# STM32U385 register map
File version: 1.0
CPU: CM33 r0p1, little endian, MPU, FPU, 4 interrupt priority bits
Registers are 32-bit, read-write, reset 0x0 unless marked. A register's access mark holds for its fields unless they carry their own. Offsets are from the block's base; [hi:lo] are bit positions; {n}, {i} and the like mark numbered series.

## PWR — PWR Address block
Base 0x40030800
Same registers: SEC_PWR 0x50030800
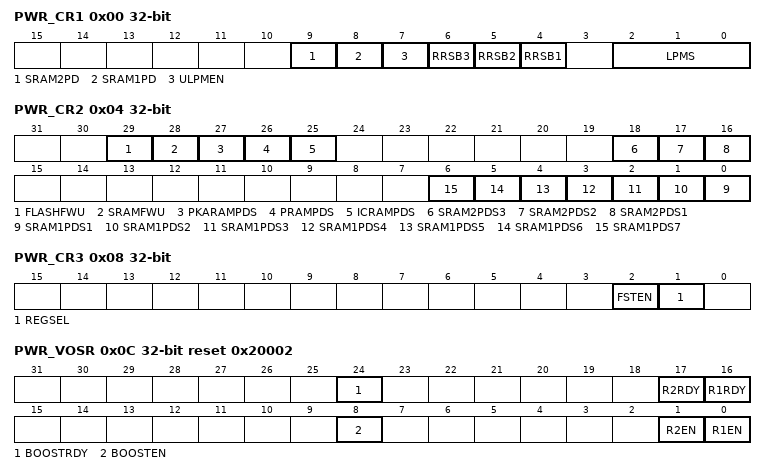
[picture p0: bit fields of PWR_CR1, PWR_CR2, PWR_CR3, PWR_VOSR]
0x00 PWR_CR1 — PWR control register 1
  [9] SRAM2PD — This bit is used to reduce the consumption by powering off the SRAM2. 0: SRAM2 powered on 1: SRAM2 powered off Note: When this bit is cleared to 0, wait for more than 1.6us before accessing the SRAM.
    0=SRAM2 powered on; 1=SRAM2 powered off
  [8] SRAM1PD — This bit is used to reduce the consumption by powering off the SRAM1. 0: SRAM1 powered on 1: SRAM1 powered off Note: When this bit is cleared to 0, wait for more than 1.6us before accessing the SRAM.
    0=SRAM1 powered on; 1=SRAM1 powered off
  [7] ULPMEN — This bit is used to reduce the consumption by configuring the BOR in discontinuous mode. This bit has effect only when the BOR level 0 is selected and when the device is in Standby mode. This bit must be set to reach the lowest power consumption in Standby mode. 0: BOR level 0 operating in continuous (normal) mode in Standby mode 1: BOR level 0 operating in discontinuous (ultra-low power) mode in Standby mode
    0=BOR level 0 operating in continuous (normal) mode in Standby mode; 1=BOR level 0 operating in discontinuous (ultra-low power) mode in Standby mode
  [6] RRSB3 — This bit is used to keep the SRAM2 page 3 content in Standby mode. The SRAM2 page 3 corresponds to the last 32 Kbytes of the SRAM2 (from SRAM2 base address + 0x8000 to SRAM2 base address + 0xFFFF). 0: SRAM2 page3 content not retained in Standby mode 1: SRAM2 page3 content retained in Standby mode Note: This bit has no effect in Shutdown mode.
    0=SRAM2 page3 content not retained in Standby mode; 1=SRAM2 page3 content retained in Standby mode
  [5] RRSB2 — This bit is used to keep the SRAM2 page 2 content in Standby mode. The SRAM2 page 2 corresponds to the 24 Kbytes of the SRAM2 (from SRAM2 base address + 0x2000 to SRAM2 base address + 0x7FFF). 0: SRAM2 page2 content not retained in Standby mode 1: SRAM2 page2 content retained in Standby mode Note: This bit has no effect in Shutdown mode.
    0=SRAM2 page2 content not retained in Standby mode; 1=SRAM2 page2 content retained in Standby mode
  [4] RRSB1 — This bit is used to keep the SRAM2 page 1 content in Standby mode. The SRAM2 page 1 corresponds to the first 8 Kbytes of the SRAM2 (from SRAM2 base address to SRAM2 base address + 0x1FFF). 0: SRAM2 page1 content not retained in Standby mode 1: SRAM2 page1 content retained in Standby mode Note: This bit has no effect in Shutdown mode.
    0=SRAM2 page1 content not retained in Standby mode; 1=SRAM2 page1 content retained in Standby mode
  [2:0] LPMS — These bits select the low-power mode entered when the CPU enters the Deepsleep mode. 000: Stop 0 mode 001: Stop 1 mode 010: Stop 2 mode 011: Stop 3 mode 100-101: Standby mode 110-111: Shutdown mode
    {v}=Stop {v} mode (v=0..3); 4=Standby mode; 5=Standby mode; 6=Shutdown mode; 7=Shutdown mode
0x04 PWR_CR2 — PWR control register 2
  [29] FLASHFWU — This bit is used to obtain the best trade-off between low-power consumption and wakeup time when exiting the Stop 0 or Stop 1 modes. When this bit is set, the Flash memory remains in normal mode in Stop 0 and Stop 1 modes, which offers a faster startup time with higher consumption. 0: Flash memory enters low-power mode in Stop 0 and Stop 1 modes (lower-power consumption). 1: Flash memory remains in normal mode in Stop 0 and Stop 1 modes (faster wakeup time).
    0=Flash memory enters low-power mode in Stop 0 and Stop 1 modes (lower-power consumption); 1=Flash memory remains in normal mode in Stop 0 and Stop 1 modes (faster wakeup time)
  [28] SRAMFWU — This bit is used to obtain the best trade-off between low-power consumption and wakeup time. SRAMs wakeup time increases the wakeup time when exiting Stop 0 and 1 modes, and also increases the GPDMA1 access time to SRAMs during Stop modes. 0: SRAMs enters low-power mode in Stop 0 and Stop 1 modes (source biasing for lower-power consumption). 1: SRAMs remains in normal mode in Stop 0 and Stop 1 modes (higher consumption but no SRAM wakeup time). Note: in case one or several SRAMs are configured to be in power-down in Stop mode, setting SRAMFWU bit has no effect.
    0=SRAMs enters low-power mode in Stop 0 and Stop 1 modes (source biasing for lower-power consumption); 1=SRAMs remains in normal mode in Stop 0 and Stop 1 modes (higher consumption but no SRAM wakeup time)
  [27] PKARAMPDS — None 0: PKA SRAM content retained in Stop modes 1: PKA SRAM content lost in Stop modes
    0=PKA SRAM content retained in Stop modes; 1=PKA SRAM content lost in Stop modes
  [26] PRAMPDS — None 0: FDCAN and USB peripherals SRAM content retained in Stop modes 1: FDCAN and USB peripherals SRAM content lost in Stop modes
    0=FDCAN and USB peripherals SRAM content retained in Stop modes; 1=FDCAN and USB peripherals SRAM content lost in Stop modes
  [25] ICRAMPDS — None 0: ICACHE SRAM content retained in Stop modes 1: ICACHE SRAM content lost in Stop modes
    0=ICACHE SRAM content retained in Stop modes; 1=ICACHE SRAM content lost in Stop modes
  [18] SRAM2PDS3 — None 0: SRAM2 page 3 content retained in Stop modes 1: SRAM2 page 3 content lost in Stop modes
    0=SRAM2 page 3 content retained in Stop modes; 1=SRAM2 page 3 content lost in Stop modes
  [17] SRAM2PDS2 — None 0: SRAM2 page 2 content retained in Stop modes 1: SRAM2 page 2 content lost in Stop modes
    0=SRAM2 page 2 content retained in Stop modes; 1=SRAM2 page 2 content lost in Stop modes
  [16] SRAM2PDS1 — None 0: SRAM2 page 1 content retained in Stop modes 1: SRAM2 page 1 content lost in Stop modes
    0=SRAM2 page 1 content retained in Stop modes; 1=SRAM2 page 1 content lost in Stop modes
  [n-1] SRAM1PDS{n} (n=1..7) — None 0: SRAM1 page {n} content retained in Stop modes 1: SRAM1 page {n} content lost in Stop modes Note: Page 1 to 2 size is 16 kBytes. Page 3 to 7 size is 32 kBytes.
    0=SRAM1 page {n} content retained in Stop modes; 1=SRAM1 page {n} content lost in Stop modes
0x08 PWR_CR3 — PWR control register 3
  [2] FSTEN — None 0: LDO/SMPS fast startup disabled (limited inrush current) 1: LDO/SMPS fast startup enabled
    0=LDO/SMPS fast startup disabled (limited inrush current); 1=LDO/SMPS fast startup enabled
  [1] REGSEL — None 0: LDO selected 1: SMPS selected Note: REGSEL is reserved and must be kept at reset value in packages without SMPS.
    0=LDO selected; 1=SMPS selected
0x0C PWR_VOSR access per field reset 0x20002 — PWR voltage scaling register
  [24] BOOSTRDY ro — This bit is set to 1 by hardware when the power booster startup time is reached. The system clock frequency can be switched higher than 24 MHz only after this bit is set. Disabling the booster clock when the booster is ready is forbidden. 0: Power booster not ready 1: Power booster ready
    0=Power booster not ready; 1=Power booster ready
  [17] R2RDY ro — None 0: Range 2 not ready: voltage level less than VOS range 2 level 1: Range 2 ready: voltage level greater or equal VOS range 2 level Note: R1RDY and R2RDY cannot be set at the same time
    0=Range 2 not ready: voltage level less than VOS range 2 level; 1=Range 2 ready: voltage level greater or equal VOS range 2 level
  [16] R1RDY ro — None 0: Range 1 not ready: voltage level less than VOS range 1 level 1: Range 1 ready: voltage level greater or equal VOS range 1 level Note: R1RDY and R2RDY cannot be set at the same time
    0=Range 1 not ready: voltage level less than VOS range 1 level; 1=Range 1 ready: voltage level greater or equal VOS range 1 level
  [8] BOOSTEN rw — This bit is protected against non-secure access when SYSCLKSEC=1 in RCC_SECCFGR. It is protected against unprivileged access when SYSCLKSEC=1 in RCC_SECCFGR and SPRIV=1 in PWR_PRIVCFGR, or when SYSCLKSEC=0 and NSPRIV=1. This bit must be set in Range 1, and before increasing the system clock frequency above 24 MHz in Range 2. The booster clock must be configured before setting this bit, and must not be disabled as long as the booster is enabled. 0: Booster disabled 1: Booster enabled
    0=Booster disabled; 1=Booster enabled
  [1] R2EN rw — This field is protected against non-secure access when SYSCLKSEC=1 in RCC_SECCFGR. It is protected against unprivileged access when SYSCLKSEC=1 in RCC_SECCFGR and SPRIV=1 in PWR_PRIVCFGR, or when SYSCLKSEC=0 and NSPRIV=1. 0: Voltage scaling range 2 disabled 1: Voltage scaling range 2 enabled Note: R1EN and R2EN must be at opposite value. Any attempt to write R1EN and R2EN to same value is ignored. Modifying R1EN and R2EN is possible only when current range is ready (R1RDY=R1EN and R2RDY=R2EN).
    0=Voltage scaling range 2 disabled; 1=Voltage scaling range 2 enabled
  [0] R1EN rw — This field is protected against non-secure access when SYSCLKSEC=1 in RCC_SECCFGR. It is protected against unprivileged access when SYSCLKSEC=1 in RCC_SECCFGR and SPRIV=1 in PWR_PRIVCFGR, or when SYSCLKSEC=0 and NSPRIV=1. 0: Voltage scaling range 1 disabled 1: Voltage scaling range 1 enabled Note: R1EN and R2EN must be at opposite value. Any attempt to write R1EN and R2EN to same value is ignored. Modifying R1EN and R2EN is possible only when current range is ready (R1RDY=R1EN and R2RDY=R2EN).
    0=Voltage scaling range 1 disabled; 1=Voltage scaling range 1 enabled
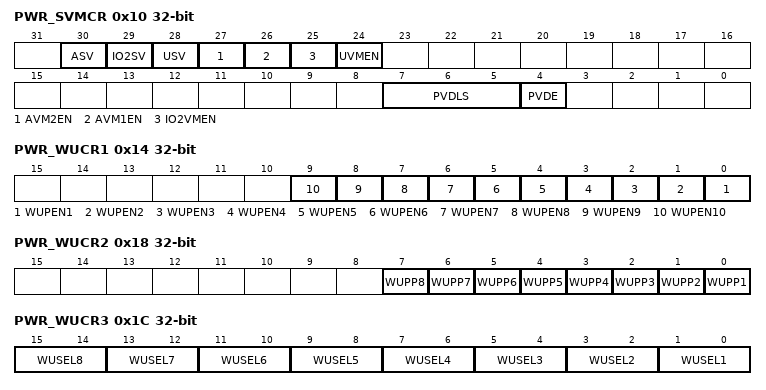
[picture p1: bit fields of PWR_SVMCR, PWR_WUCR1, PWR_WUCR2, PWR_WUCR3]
0x10 PWR_SVMCR — PWR supply voltage monitoring control register
  [30] ASV — This bit is used to validate the VDDA supply for electrical and logical isolation purpose. Setting this bit is mandatory to use the analog peripherals. If VDDA is not always present in the application, the VDDA voltage monitor can be used to determine whether this supply is ready or not. 0: VDDA not present: logical and electrical isolation is applied to ignore this supply. 1: VDDA valid
    0=VDDA not present: logical and electrical isolation is applied to ignore this supply; 1=VDDA valid
  [29] IO2SV — This bit is used to validate the VDDIO2 supply for electrical and logical isolation purpose. Setting this bit is mandatory to use PG[15:2]. If VDDIO2 is not always present in the application, the VDDIO2 voltage monitor can be used to determine whether this supply is ready or not. 0: VDDIO2 not present: logical and electrical isolation is applied to ignore this supply. 1: VDDIO2 valid
    0=VDDIO2 not present: logical and electrical isolation is applied to ignore this supply; 1=VDDIO2 valid
  [28] USV — This bit is used to validate the VDDUSB supply for electrical and logical isolation purpose. Setting this bit is mandatory to use the USB peripheral. If VDDUSB is not always present in the application, the VDDUSB voltage monitor can be used to determine whether this supply is ready or not. 0: VDDUSB not present: logical and electrical isolation is applied to ignore this supply. 1: VDDUSB valid
    0=VDDUSB not present: logical and electrical isolation is applied to ignore this supply; 1=VDDUSB valid
  [27] AVM2EN — None 0: VDDA voltage monitor 2 disabled 1: VDDA voltage monitor 2 enabled
    0=VDDA voltage monitor 2 disabled; 1=VDDA voltage monitor 2 enabled
  [26] AVM1EN — None 0: VDDA voltage monitor 1 disabled 1: VDDA voltage monitor 1 enabled
    0=VDDA voltage monitor 1 disabled; 1=VDDA voltage monitor 1 enabled
  [25] IO2VMEN — None 0: VDDIO2 voltage monitor disabled 1: VDDIO2 voltage monitor enabled
    0=VDDIO2 voltage monitor disabled; 1=VDDIO2 voltage monitor enabled
  [24] UVMEN — None 0: VDDUSB voltage monitor disabled 1: VDDUSB voltage monitor enabled
    0=VDDUSB voltage monitor disabled; 1=VDDUSB voltage monitor enabled
  [7:5] PVDLS — These bits select the voltage threshold detected by the PVD: 000: VPVD0 around 2.0V 001: VPVD1 around 2.2V 010: VPVD2 around 2.4V 011: VPVD3 around 2.5V 100: VPVD4 around 2.6V 101: VPVD5 around 2.8V 110: VPVD6 around 2.9V 111: External input analog voltage PVD_IN (compared internally to VREFINT)
    0=VPVD0 around 2.0V; 1=VPVD1 around 2.2V; 2=VPVD2 around 2.4V; 3=VPVD3 around 2.5V; 4=VPVD4 around 2.6V; 5=VPVD5 around 2.8V; 6=VPVD6 around 2.9V; 7=External input analog voltage PVD_IN (compared internally to VREFINT)
  [4] PVDE — None 0: PVD disabled 1: PVD enabled
    0=PVD disabled; 1=PVD enabled
0x14 PWR_WUCR1 — PWR wakeup control register 1
  [n-1] WUPEN{n} (n=1..10) — None 0: Wakeup line WKUP{n} disabled 1: Wakeup line WKUP{n} enabled
    0=Wakeup line WKUP{n} disabled; 1=Wakeup line WKUP{n} enabled
0x18 PWR_WUCR2 — PWR wakeup control register 2
  [all] fields
    0=Detection on high level (rising edge); 1=Detection on low level (falling edge)
  [n-1] WUPP{n} (n=1..8) — This bit must be configured when WUPEN{n} = 0. It has no effect when WUSEL{n} = 11. 0: Detection on high level (rising edge) 1: Detection on low level (falling edge)
0x1C PWR_WUCR3 — PWR wakeup control register 3
  [2n-1:2n-2] WUSEL{n} (n=1..8) — This field must be configured when WUPEN{n} = 0. 00: WKUP{n}_0 01: WKUP{n}_1 10: WKUP{n}_2 11: WKUP{n}_3
    {v}=WKUP{n}_{v} (v=0..3)
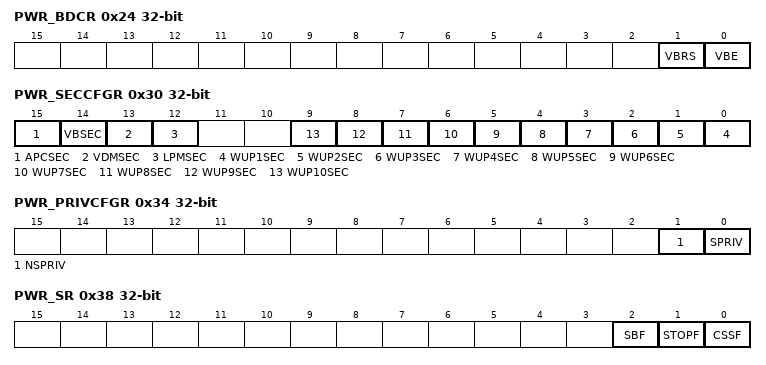
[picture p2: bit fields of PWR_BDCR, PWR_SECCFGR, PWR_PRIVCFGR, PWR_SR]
0x24 PWR_BDCR — PWR Backup domain control register
  [1] VBRS — None 0: Charge VBAT through a 5 k ohm resistor 1: Charge VBAT through a 1.5 k ohm resistor
    0=Charge VBAT through a 5 k ohm resistor; 1=Charge VBAT through a 1.5 k ohm resistor
  [0] VBE — None 0: VBAT battery charging disabled 1: VBAT battery charging enabled
    0=VBAT battery charging disabled; 1=VBAT battery charging enabled
0x28 PWR_DBPR — PWR disable Backup domain register
  [0] DBP — In reset state, all registers and SRAM in Backup domain are protected against parasitic write access. This bit must be set to enable the write access to these registers. 0: Write access to Backup domain disabled 1: Write access to Backup domain enabled
    0=Write access to Backup domain disabled; 1=Write access to Backup domain enabled
0x30 PWR_SECCFGR — PWR security configuration register
  [15] APCSEC — None 0: PWR_APCR can be read and written with secure or non-secure access. 1: PWR_APCR can be read and written only with secure access.
    0=PWR_APCR can be read and written with secure or non-secure access; 1=PWR_APCR can be read and written only with secure access
  [14] VBSEC — None 0: PWR_BDCR and PWR_DBPR can be read and written with secure or non-secure access. 1: PWR_BDCR and PWR_DBPR can be read and written only with secure access.
    0=PWR_BDCR and PWR_DBPR can be read and written with secure or non-secure access; 1=PWR_BDCR and PWR_DBPR can be read and written only with secure access
  [13] VDMSEC — None 0: PWR_SVMCR and PWR_CR3 can be read and written with secure or non-secure access. 1: PWR_SVMCR and PWR_CR3 can be read and written only with secure access.
    0=PWR_SVMCR and PWR_CR3 can be read and written with secure or non-secure access; 1=PWR_SVMCR and PWR_CR3 can be read and written only with secure access
  [12] LPMSEC — None 0: PWR_CR1, PWR_CR2 and CSSF in the PWR_SR can be read and written with secure or non-secure access. 1: PWR_CR1, PWR_CR2, and CSSF in the PWR_SR can be read and written only with secure access.
    0=PWR_CR1, PWR_CR2 and CSSF in the PWR_SR can be read and written with secure or non-secure access; 1=PWR_CR1, PWR_CR2, and CSSF in the PWR_SR can be read and written only with secure access
  [n-1] WUP{n}SEC (n=1..10) — None 0: Bits related to the WKUP{n} line in PWR_WUCR1, PWR_WUCR2, PWR_WUCR3 and PWR_WUSCR can be read and written with secure or non-secure access. 1: Bits related to the WKUP{n} line in PWR_WUCR1, PWR_WUCR2, PWR_WUCR3 and PWR_WUSCR can be read and written only with secure access.
    0=Bits related to the WKUP{n} line in PWR_WUCR1, PWR_WUCR2, PWR_WUCR3 and PWR_WUSCR can be read and written with secure or non-secure access; 1=Bits related to the WKUP{n} line in PWR_WUCR1, PWR_WUCR2, PWR_WUCR3 and PWR_WUSCR can be read and written only with secure access
0x34 PWR_PRIVCFGR — PWR privilege control register
  [1] NSPRIV — This bit is set and reset by software. It can be written only by privileged access, secure or non-secure. 0: Read and write to PWR non-secure functions can be done by privileged or unprivileged access. 1: Read and write to PWR non-secure functions can be done by privileged access only.
    0=Read and write to PWR non-secure functions can be done by privileged or unprivileged access; 1=Read and write to PWR non-secure functions can be done by privileged access only
  [0] SPRIV — This bit is set and reset by software. It can be written only by a secure privileged access. 0: Read and write to PWR secure functions can be done by privileged or unprivileged access. 1: Read and write to PWR secure functions can be done by privileged access only.
    0=Read and write to PWR secure functions can be done by privileged or unprivileged access; 1=Read and write to PWR secure functions can be done by privileged access only
0x38 PWR_SR access per field — PWR status register
  [2] SBF ro — This bit is set by hardware when the device enters the Standby mode, and is cleared by writing 1 to the CSSF bit, or by a power-on reset. It is not cleared by the system reset. 0: The device did not enter Standby mode. 1: The device entered Standby mode.
    0=The device did not enter Standby mode; 1=The device entered Standby mode
  [1] STOPF ro — This bit is set by hardware when the device enters a Stop mode, and is cleared by software by writing 1 to the CSSF bit. 0: The device did not enter any Stop mode. 1: The device entered a Stop mode.
    0=The device did not enter any Stop mode; 1=The device entered a Stop mode
  [0] CSSF wo — This bit is protected against non-secure access when LPMSEC=1 in PWR_SECCFGR. This bit is protected against unprivileged access when LPMSEC=1 and SPRIV=1 in PWR_PRIVCFGR, or when LPMSEC=0 and NSPRIV=1. Writing 1 to this bit clears the STOPF and SBF flags.
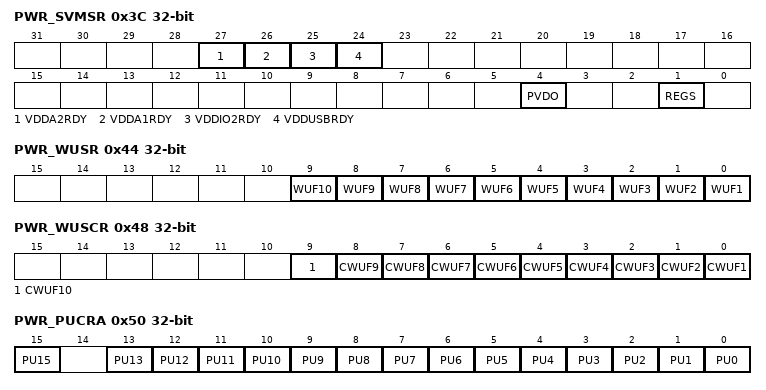
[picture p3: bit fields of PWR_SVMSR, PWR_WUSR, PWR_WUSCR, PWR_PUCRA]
0x3C PWR_SVMSR ro — PWR supply voltage monitoring status register
  [27] VDDA2RDY — None 0: VDDA is below the threshold of the VDDA voltage monitor 2 (around 1.8V). 1: VDDA is equal or above the threshold of the VDDA voltage monitor 2 (around 1.8V).
    0=VDDA is below the threshold of the VDDA voltage monitor 2 (around 1.8V); 1=VDDA is equal or above the threshold of the VDDA voltage monitor 2 (around 1.8V)
  [26] VDDA1RDY — None 0: VDDA is below the threshold of the VDDA voltage monitor 1 (around 1.6V). 1: VDDA is equal or above the threshold of the VDDA voltage monitor 1 (around 1.6V).
    0=VDDA is below the threshold of the VDDA voltage monitor 1 (around 1.6V); 1=VDDA is equal or above the threshold of the VDDA voltage monitor 1 (around 1.6V)
  [25] VDDIO2RDY — None 0: VDDIO2 is below the threshold of the VDDIO2 voltage monitor. 1: VDDIO2 is equal or above the threshold of the VDDIO2 voltage monitor.
    0=VDDIO2 is below the threshold of the VDDIO2 voltage monitor; 1=VDDIO2 is equal or above the threshold of the VDDIO2 voltage monitor
  [24] VDDUSBRDY — None 0: VDDUSB is below the threshold of the VDDUSB voltage monitor. 1: VDDUSB is equal or above the threshold of the VDDUSB voltage monitor.
    0=VDDUSB is below the threshold of the VDDUSB voltage monitor; 1=VDDUSB is equal or above the threshold of the VDDUSB voltage monitor
  [4] PVDO — None 0: VDD is equal or above the PVD threshold selected by PVDLS[2:0]. 1: VDD is below the PVD threshold selected by PVDLS[2:0].
    0=VDD is equal or above the PVD threshold selected by PVDLS[2:0]; 1=VDD is below the PVD threshold selected by PVDLS[2:0]
  [1] REGS — None 0: LDO selected 1: SMPS selected
    0=LDO selected; 1=SMPS selected
0x44 PWR_WUSR ro — PWR wakeup status register
  [n-1] WUF{n} (n=1..10) — This bit is set when a wakeup event is detected on WKUP{n} line. This bit is cleared by writing 1 in the CWUF{n} bit of PWR_WUSCR when WUSEL different 11, or by hardware when WUPEN{n}=0. If WUSEL = 11, this bit is cleared by hardware when all internal wakeup source are cleared.
0x48 PWR_WUSCR wo — PWR wakeup status clear register
  [n-1] CWUF{n} (n=1..10) — Writing 1 to this bit clears the WUF{n} flag in PWR_WUSR.
0x4C PWR_APCR — PWR apply pull configuration register
  [0] APC — When this bit is set, the I/O pull-up and pull-down configurations defined in PWR_PUCRx and PWR_PDCRx are applied. When this bit is cleared, PWR_PUCRx and PWR_PDCRx are not applied to the I/Os.
0x50 PWR_PUCRA — PWR port A pull-up control register
  [15] PU15 — When set, each bit activates the pull-up on PA15 when the APC bit is set in PWR_APCR. The pull-up is not activated if the corresponding PD15 bit is also set. Note: The bit is reserved and must be kept to reset value when the corresponding I/O is not available on the selected package.
  [n] PU{n} (n=0..13) — When set, each bit activates the pull-up on PA{n} when the APC bit is set in PWR_APCR. The pull-up is not activated if the corresponding PD{n} bit is also set. Note: The bit is reserved and must be kept to reset value when the corresponding I/O is not available on the selected package.
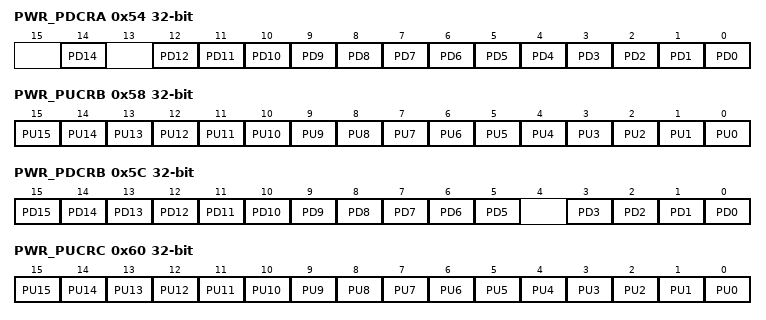
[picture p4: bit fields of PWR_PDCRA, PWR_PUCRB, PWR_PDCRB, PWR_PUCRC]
0x54 PWR_PDCRA — PWR port A pull-down control register
  [14] PD14 — When set, each bit activates the pull-down on PA14 when the APC bit is set in PWR_APCR. Note: The bit is reserved and must be kept to reset value when the corresponding I/O is not available on the selected package.
  [n] PD{n} (n=0..12) — When set, each bit activates the pull-down on PA{n} when the APC bit is set in PWR_APCR. Note: The bit is reserved and must be kept to reset value when the corresponding I/O is not available on the selected package.
0x58 PWR_PUCRB — PWR port B pull-up control register
  [n] PU{n} (n=0..15) — When set, each bit activates the pull-up on PB{n} when the APC bit is set in PWR_APCR. The pull-up is not activated if the corresponding PD{n} bit is also set. Note: The bit is reserved and must be kept to reset value when the corresponding I/O is not available on the selected package.
0x5C PWR_PDCRB — PWR port B pull-down control register
  [n] PD{n} (n=5..15) — When set, each bit activates the pull-down on PB{n} when the APC bit is set in PWR_APCR. Note: The bit is reserved and must be kept to reset value when the corresponding I/O is not available on the selected package.
  [n] PD{n} (n=0..3) — When set, each bit activates the pull-down on PB{n} when the APC bit is set in PWR_APCR. Note: The bit is reserved and must be kept to reset value when the corresponding I/O is not available on the selected package.
0x60 PWR_PUCRC — PWR port C pull-up control register
  [n] PU{n} (n=0..15) — When set, each bit activates the pull-up on PC{n} when the APC bit is set in PWR_APCR. The pull-up is not activated if the corresponding PD{n} bit is also set. Note: The bit is reserved and must be kept to reset value when the corresponding I/O is not available on the selected package.
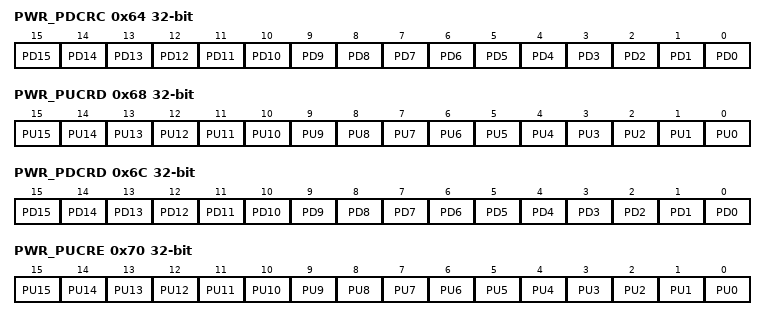
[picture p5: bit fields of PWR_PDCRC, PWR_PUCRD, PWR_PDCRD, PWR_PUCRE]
0x64 PWR_PDCRC — PWR port C pull-down control register
  [n] PD{n} (n=0..15) — When set, each bit activates the pull-down on PC{n} when the APC bit is set in PWR_APCR. Note: The bit is reserved and must be kept to reset value when the corresponding I/O is not available on the selected package.
0x68 PWR_PUCRD — PWR port D pull-up control register
  [n] PU{n} (n=0..15) — When set, each bit activates the pull-up on PD{n} when the APC bit is set in PWR_APCR. The pull-up is not activated if the corresponding PD{n} bit is also set. Note: The bit is reserved and must be kept to reset value when the corresponding I/O is not available on the selected package.
0x6C PWR_PDCRD — PWR port D pull-down control register
  [n] PD{n} (n=0..15) — When set, each bit activates the pull-down on PD{n} when the APC bit is set in PWR_APCR. Note: The bit is reserved and must be kept to reset value when the corresponding I/O is not available on the selected package.
0x70 PWR_PUCRE — PWR port E pull-up control register
  [n] PU{n} (n=0..15) — When set, each bit activates the pull-up on PE{n} when the APC bit is set in PWR_APCR. The pull-up is not activated if the corresponding PD{n} bit is also set. Note: The bit is reserved and must be kept to reset value when the corresponding I/O is not available on the selected package.
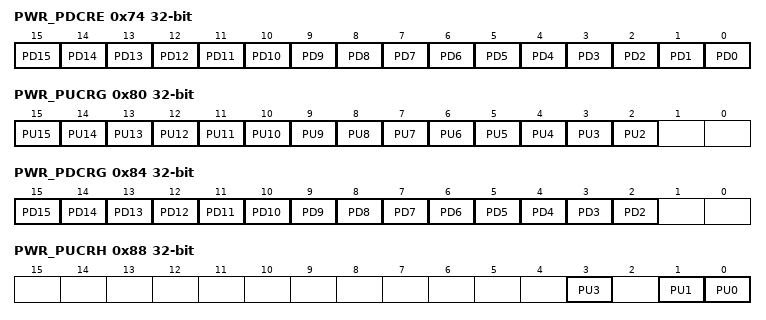
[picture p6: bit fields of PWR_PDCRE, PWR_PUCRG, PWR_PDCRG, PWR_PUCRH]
0x74 PWR_PDCRE — PWR port E pull-down control register
  [n] PD{n} (n=0..15) — When set, each bit activates the pull-down on PE{n} when the APC bit is set in PWR_APCR. Note: The bit is reserved and must be kept to reset value when the corresponding I/O is not available on the selected package.
0x80 PWR_PUCRG — PWR port G pull-up control register
  [n] PU{n} (n=2..15) — When set, each bit activates the pull-up on PG{n} when the APC bit is set in PWR_APCR. The pull-up is not activated if the corresponding PD{n} bit is also set. Note: The bit is reserved and must be kept to reset value when the corresponding I/O is not available on the selected package.
0x84 PWR_PDCRG — PWR port G pull-down control register
  [n] PD{n} (n=2..15) — When set, each bit activates the pull-down on PG{n} when the APC bit is set in PWR_APCR. Note: The bit is reserved and must be kept to reset value when the corresponding I/O is not available on the selected package.
0x88 PWR_PUCRH — PWR port H pull-up control register
  [3] PU3 — When set, each bit activates the pull-up on PH3 when the APC bit is set in PWR_APCR. The pull-up is not activated if the corresponding PD3 bit is also set. Note: The bit is reserved and must be kept to reset value when the corresponding I/O is not available on the selected package.
  [1] PU1 — When set, each bit activates the pull-up on PH1 when the APC bit is set in PWR_APCR. The pull-up is not activated if the corresponding PD1 bit is also set. Note: The bit is reserved and must be kept to reset value when the corresponding I/O is not available on the selected package.
  [0] PU0 — When set, each bit activates the pull-up on PH0 when the APC bit is set in PWR_APCR. The pull-up is not activated if the corresponding PD0 bit is also set. Note: The bit is reserved and must be kept to reset value when the corresponding I/O is not available on the selected package.
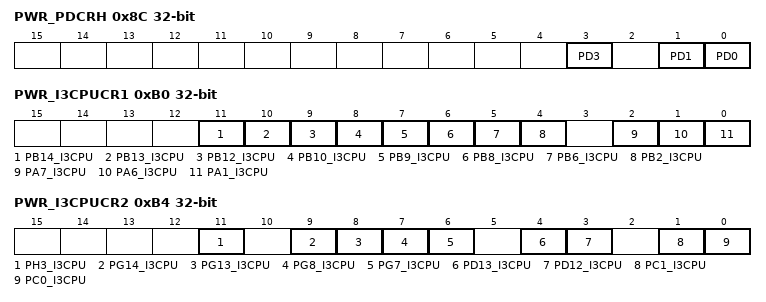
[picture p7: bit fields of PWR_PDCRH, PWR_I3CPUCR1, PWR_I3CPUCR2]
0x8C PWR_PDCRH — PWR port H pull-down control register
  [3] PD3 — When set, each bit activates the pull-down on PH3 when the APC bit is set in PWR_APCR. Note: The bit is reserved and must be kept to reset value when the corresponding I/O is not available on the selected package.
  [1] PD1 — When set, each bit activates the pull-down on PH1 when the APC bit is set in PWR_APCR. Note: The bit is reserved and must be kept to reset value when the corresponding I/O is not available on the selected package.
  [0] PD0 — When set, each bit activates the pull-down on PH0 when the APC bit is set in PWR_APCR. Note: The bit is reserved and must be kept to reset value when the corresponding I/O is not available on the selected package.
0xB0 PWR_I3CPUCR1 — PWR I3C pull-up control register 1
  [11] PB14_I3CPU — When set, the bit activates the I3C pull-up on PB14.
  [10] PB13_I3CPU — When set, the bit activates the I3C pull-up on PB13.
  [9] PB12_I3CPU — When set, the bit activates the I3C pull-up on PB12.
  [8] PB10_I3CPU — When set, the bit activates the I3C pull-up on PB10.
  [7] PB9_I3CPU — When set, the bit activates the I3C pull-up on PB9.
  [6] PB8_I3CPU — When set, the bit activates the I3C pull-up on PB8.
  [5] PB6_I3CPU — When set, the bit activates the I3C pull-up on PB6.
  [4] PB2_I3CPU — When set, the bit activates the I3C pull-up on PB2.
  [2] PA7_I3CPU — When set, the bit activates the I3C pull-up on PA7.
  [1] PA6_I3CPU — When set, the bit activates the I3C pull-up on PA6.
  [0] PA1_I3CPU — When set, the bit activates the I3C pull-up on PA1.
0xB4 PWR_I3CPUCR2 — PWR I3C pull-up control register 2
  [11] PH3_I3CPU — When set, the bit activates the I3C pull-up on PH3.
  [9] PG14_I3CPU — When set, the bit activates the I3C pull-up on PG14.
  [8] PG13_I3CPU — When set, the bit activates the I3C pull-up on PG13.
  [7] PG8_I3CPU — When set, the bit activates the I3C pull-up on PG8.
  [6] PG7_I3CPU — When set, the bit activates the I3C pull-up on PG7.
  [4] PD13_I3CPU — When set, the bit activates the I3C pull-up on PD13.
  [3] PD12_I3CPU — When set, the bit activates the I3C pull-up on PD12.
  [1] PC1_I3CPU — When set, the bit activates the I3C pull-up on PC1.
  [0] PC0_I3CPU — When set, the bit activates the I3C pull-up on PC0.
